# ATxmega16E5 device description
Architecture: AVR8_XMEGA; Family: AVR XMEGA
Registers are 8-bit, access not given, no defined reset value unless marked. A register's access mark holds for its fields unless they carry their own. Offsets are from the block's base; [hi:lo] are bit positions; {n}, {i} and the like mark numbered series; 'fields as' and 'values as' point back to an identical list.

## DFLL
Instances: DFLLRC32M 0x0060
0x00 CTRL — Control Register
  [0] ENABLE — DFLL Enable
0x02 CALA — Calibration Register A
  [6:0] CALL — DFLL Calibration Value A
0x03 CALB — Calibration Register B
  [5:0] CALH — DFLL Calibration Value B
{0x4+i} COMP{i} (i=0..2) — Oscillator Compare Register {i}

## RST — Reset
Instances: RST 0x0078
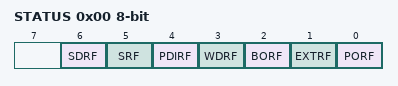
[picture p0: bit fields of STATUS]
0x00 STATUS
  [6] SDRF — Spike Detection Reset Flag
  [5] SRF — Software Reset Flag
  [4] PDIRF — Programming and Debug Interface Interface Reset Flag
  [3] WDRF — Watchdog Reset Flag
  [2] BORF — Brown-out Reset Flag
  [1] EXTRF — External Reset Flag
  [0] PORF — Power-on Reset Flag
0x01 CTRL — Control Register
  [0] SWRST — Software Reset

## WDT — Watch-Dog Timer
Instances: WDT 0x0080
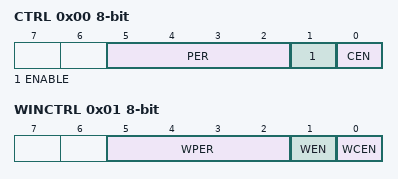
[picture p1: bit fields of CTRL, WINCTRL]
0x00 CTRL — Control
  [5:2] PER — Period
    0=8CLK (8 cycles (8ms @ 3.3V)); 1=16CLK (16 cycles (16ms @ 3.3V)); 2=32CLK (32 cycles (32ms @ 3.3V)); 3=64CLK (64 cycles (64ms @ 3.3V)); 4=128CLK (128 cycles (0.128s @ 3.3V)); 5=256CLK (256 cycles (0.256s @ 3.3V)); 6=512CLK (512 cycles (0.512s @ 3.3V)); 7=1KCLK (1K cycles (1s @ 3.3V)); 8=2KCLK (2K cycles (2s @ 3.3V)); 9=4KCLK (4K cycles (4s @ 3.3V)); 10=8KCLK (8K cycles (8s @ 3.3V))
  [1] ENABLE
  [0] CEN — Change Enable
0x01 WINCTRL — Windowed Mode Control
  [5:2] WPER — Windowed Mode Period
    values as CTRL.PER
  [1] WEN — Windowed Mode Enable
  [0] WCEN — Windowed Mode Change Enable
0x02 STATUS
  [0] SYNCBUSY — Syncronization busy

## MCU — MCU Control
Instances: MCU 0x0090
{0x0+i} DEVID{i} (i=0..2) — Device ID byte {i}
0x03 REVID — Revision ID
0x07 ANAINIT — Analog Startup Delay
  [1:0] STARTUPDLYA — Analog startup delay Port A
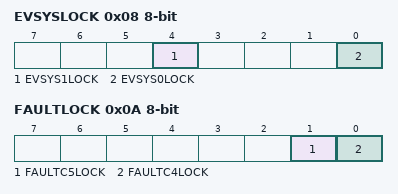
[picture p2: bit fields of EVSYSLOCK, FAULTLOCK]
0x08 EVSYSLOCK — Event System Lock
  [4] EVSYS1LOCK — Event Channel 4-7 Lock
  [0] EVSYS0LOCK — Event Channel 0-3 Lock
0x09 WEXLOCK
  [0] WEXCLOCK — WeX on T/C C4 Lock
0x0A FAULTLOCK
  [1] FAULTC5LOCK — Fault on T/C C5 Lock
  [0] FAULTC4LOCK — Fault on T/C C4 Lock

## PMIC — Programmable Multi-level Interrupt Controller
Instances: PMIC 0x00A0
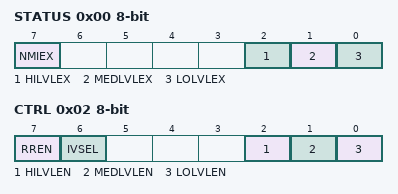
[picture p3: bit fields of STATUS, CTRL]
0x00 STATUS
  [7] NMIEX — Non-maskable Interrupt Executing
  [2] HILVLEX — High Level Interrupt Executing
  [1] MEDLVLEX — Medium Level Interrupt Executing
  [0] LOLVLEX — Low Level Interrupt Executing
0x01 INTPRI — Interrupt Priority
0x02 CTRL — Control Register
  [7] RREN — Round-Robin Priority Enable
  [6] IVSEL — Interrupt Vector Select
  [2] HILVLEN — High Level Enable
  [1] MEDLVLEN — Medium Level Enable
  [0] LOLVLEN — Low Level Enable

## PORTCFG — I/O port Configuration
Instances: PORTCFG 0x00B0
0x00 MPCMASK — Multi-pin Configuration Mask
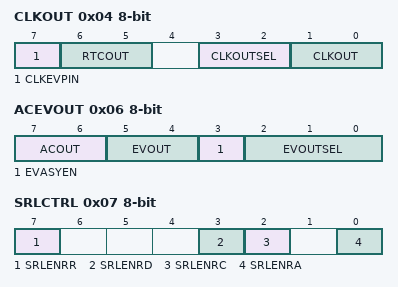
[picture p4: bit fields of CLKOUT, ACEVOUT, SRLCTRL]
0x04 CLKOUT — Clock Out Register
  [7] CLKEVPIN — Clock and Event Output Pin Select
    0=PIN7 (Clock and Event Output on PIN 7); 1=PIN4 (Clock and Event Output on PIN 4)
  [6:5] RTCOUT — RTC Clock Output Enable
    0=OFF (System Clock Output Disabled); 1=PC6 (System Clock Output on Port C pin 6); 2=PD6 (System Clock Output on Port D pin 6); 3=PR0 (System Clock Output on Port R pin 0)
  [3:2] CLKOUTSEL — Clock Output Select
    0=CLK1X (1x Peripheral Clock Output to pin); 1=CLK2X (2x Peripheral Clock Output to pin); 2=CLK4X (4x Peripheral Clock Output to pin)
  [1:0] CLKOUT — Clock Output Port
    0=OFF (System Clock Output Disabled); 1=PC7 (System Clock Output on Port C pin 7); 2=PD7 (System Clock Output on Port D pin 7); 3=PR0 (System Clock Output on Port R pin 0)
0x06 ACEVOUT — Analog Comparator and Event Out Register
  [7:6] ACOUT — Analog Comparator Output Port
    0=PA (Analog Comparator Outputs on Port A, Pin 6-7); 1=PC (Analog Comparator Outputs on Port C, Pin 6-7); 2=PD (Analog Comparator Outputs on Port D, Pin 6-7); 3=PR (Analog Comparator Outputs on Port R, Pin 0-1)
  [5:4] EVOUT — Event Channel Output Port
    0=OFF (Event Output Disabled); 1=PC7 (Event Channel n Output on Port C pin 7); 2=PD7 (Event Channel n Output on Port D pin 7); 3=PR0 (Event Channel n Output on Port R pin 0)
  [3] EVASYEN — Asynchronous Event Enabled
  [2:0] EVOUTSEL — Event Channel Output Selection
    {v}=Event Channel {v} output to pin (v=0..7)
0x07 SRLCTRL — Slew Rate Limit Control Register
  [7] SRLENRR — Slew Rate Limit Enable on PORTR
  [3] SRLENRD — Slew Rate Limit Enable on PORTD
  [2] SRLENRC — Slew Rate Limit Enable on PORTC
  [0] SRLENRA — Slew Rate Limit Enable on PORTA
